VERSION ""

NS_ :

BS_:

BU_: BMS Third_Party_Device

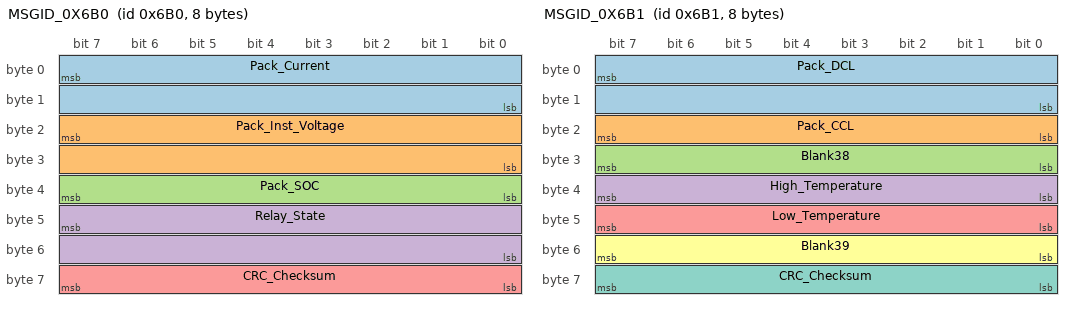
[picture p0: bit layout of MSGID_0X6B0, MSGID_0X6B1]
BO_ 1712 MSGID_0X6B0: 8 BMS
 SG_ Pack_Current : 7|16@0+ (0.1,0) [0|0] "Amps"  Third_Party_Device
 SG_ Pack_Inst_Voltage : 23|16@0+ (0.1,0) [0|0] "Volts"  Third_Party_Device
 SG_ Pack_SOC : 39|8@0+ (0.5,0) [0|0] "Percent"  Third_Party_Device
 SG_ Relay_State : 47|16@0+ (1.0,0) [0|0] ""  Third_Party_Device
 SG_ CRC_Checksum : 63|8@0+ (1.0,1720) [0|0] ""  Third_Party_Device

BO_ 1713 MSGID_0X6B1: 8 BMS
 SG_ Pack_DCL : 7|16@0+ (1.0,0) [0|0] "Amps"  Third_Party_Device
 SG_ Pack_CCL : 23|8@0+ (1.0,0) [0|0] "Amps"  Third_Party_Device
 SG_ Blank38 : 31|8@0+ (1.0,0) [0|0] ""  Third_Party_Device
 SG_ High_Temperature : 39|8@0+ (1.0,0) [0|0] "Celsius"  Third_Party_Device
 SG_ Low_Temperature : 47|8@0+ (1.0,0) [0|0] "Celsius"  Third_Party_Device
 SG_ Blank39 : 55|8@0+ (1.0,0) [0|0] ""  Third_Party_Device
 SG_ CRC_Checksum : 63|8@0+ (1.0,1721) [0|0] ""  Third_Party_Device

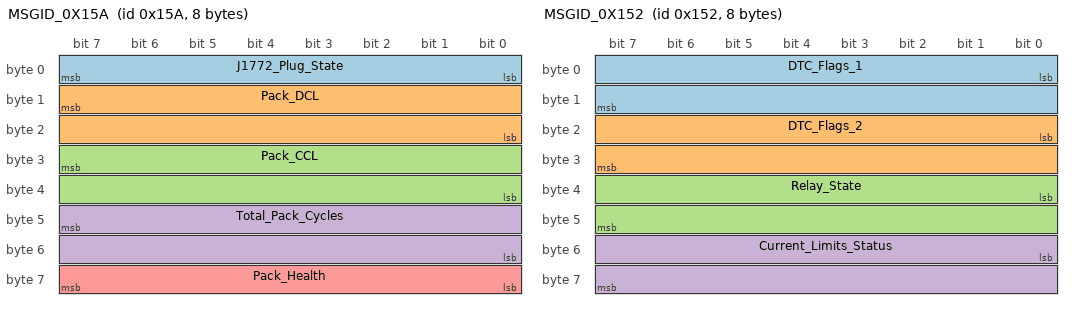
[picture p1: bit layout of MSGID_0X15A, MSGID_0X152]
BO_ 346 MSGID_0X15A: 8 BMS
 SG_ J1772_Plug_State : 7|8@0+ (1.0,0) [0|0] ""  Third_Party_Device
 SG_ Pack_DCL : 15|16@0+ (1.0,0) [0|0] "Amps"  Third_Party_Device
 SG_ Pack_CCL : 31|16@0+ (1.0,0) [0|0] "Amps"  Third_Party_Device
 SG_ Total_Pack_Cycles : 47|16@0+ (1.0,0) [0|0] "Num"  Third_Party_Device
 SG_ Pack_Health : 63|8@0+ (1.0,0) [0|0] "Percent"  Third_Party_Device

BO_ 338 MSGID_0X152: 8 BMS
 SG_ DTC_Flags_1 : 0|16@1+ (1.0,0) [0|0] ""  Third_Party_Device
 SG_ DTC_Flags_2 : 16|16@1+ (1.0,0) [0|0] ""  Third_Party_Device
 SG_ Relay_State : 32|16@1+ (1.0,0) [0|0] ""  Third_Party_Device
 SG_ Current_Limits_Status : 48|16@1+ (1.0,0) [0|0] ""  Third_Party_Device

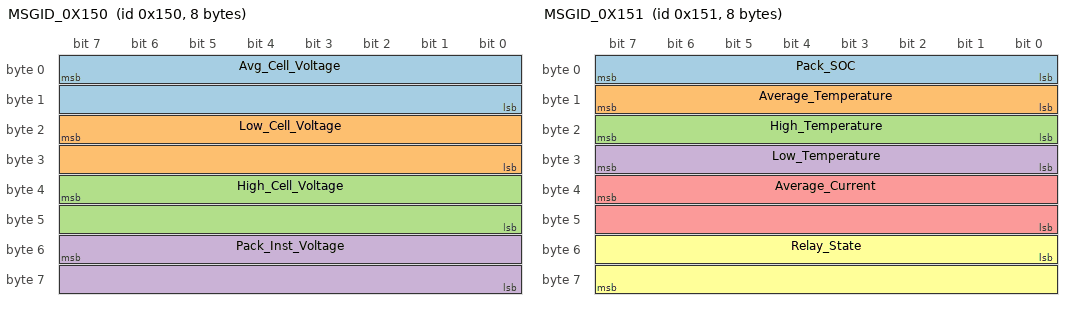
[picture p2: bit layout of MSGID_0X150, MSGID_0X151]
BO_ 336 MSGID_0X150: 8 BMS
 SG_ Avg_Cell_Voltage : 7|16@0+ (1.0E-4,0) [0|0] "Volts"  Third_Party_Device
 SG_ Low_Cell_Voltage : 23|16@0+ (1.0E-4,0) [0|0] "Volts"  Third_Party_Device
 SG_ High_Cell_Voltage : 39|16@0+ (1.0E-4,0) [0|0] "Volts"  Third_Party_Device
 SG_ Pack_Inst_Voltage : 55|16@0+ (0.1,0) [0|0] "Volts"  Third_Party_Device

BO_ 337 MSGID_0X151: 8 BMS
 SG_ Pack_SOC : 7|8@0+ (0.5,0) [0|0] "Percent"  Third_Party_Device
 SG_ Average_Temperature : 15|8@0+ (1.0,0) [0|0] "Celsius"  Third_Party_Device
 SG_ High_Temperature : 23|8@0+ (1.0,0) [0|0] "Celsius"  Third_Party_Device
 SG_ Low_Temperature : 31|8@0+ (1.0,0) [0|0] "Celsius"  Third_Party_Device
 SG_ Average_Current : 39|16@0+ (0.1,0) [0|0] "Amps"  Third_Party_Device
 SG_ Relay_State : 48|16@1+ (1.0,0) [0|0] ""  Third_Party_Device

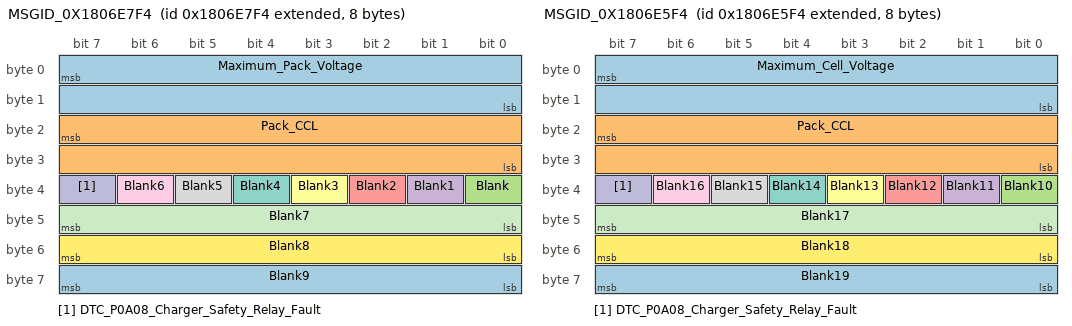
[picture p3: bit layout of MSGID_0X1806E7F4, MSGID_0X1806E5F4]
BO_ 2550589428 MSGID_0X1806E7F4: 8 BMS
 SG_ Maximum_Pack_Voltage : 7|16@0+ (0.1,0) [0|0] "Volts"  Third_Party_Device
 SG_ Pack_CCL : 23|16@0+ (0.1,0) [0|0] "Amps"  Third_Party_Device
 SG_ Blank : 32|1@1+ (1.0,0) [0|1] ""  Third_Party_Device
 SG_ Blank1 : 33|1@1+ (1.0,0) [0|1] ""  Third_Party_Device
 SG_ Blank2 : 34|1@1+ (1.0,0) [0|1] ""  Third_Party_Device
 SG_ Blank3 : 35|1@1+ (1.0,0) [0|1] ""  Third_Party_Device
 SG_ Blank4 : 36|1@1+ (1.0,0) [0|1] ""  Third_Party_Device
 SG_ Blank5 : 37|1@1+ (1.0,0) [0|1] ""  Third_Party_Device
 SG_ Blank6 : 38|1@1+ (1.0,0) [0|1] ""  Third_Party_Device
 SG_ DTC_P0A08_Charger_Safety_Relay_Fault : 39|1@1+ (1.0,0) [0|1] ""  Third_Party_Device
 SG_ Blank7 : 47|8@0+ (0.1,0) [0|0] ""  Third_Party_Device
 SG_ Blank8 : 55|8@0+ (1.0,0) [0|0] ""  Third_Party_Device
 SG_ Blank9 : 63|8@0+ (1.0,0) [0|0] ""  Third_Party_Device

BO_ 2550588916 MSGID_0X1806E5F4: 8 BMS
 SG_ Maximum_Cell_Voltage : 7|16@0+ (0.002777777777777778,0) [0|0] "Volts"  Third_Party_Device
 SG_ Pack_CCL : 23|16@0+ (0.1,0) [0|0] "Amps"  Third_Party_Device
 SG_ Blank10 : 32|1@1+ (1.0,0) [0|1] ""  Third_Party_Device
 SG_ Blank11 : 33|1@1+ (1.0,0) [0|1] ""  Third_Party_Device
 SG_ Blank12 : 34|1@1+ (1.0,0) [0|1] ""  Third_Party_Device
 SG_ Blank13 : 35|1@1+ (1.0,0) [0|1] ""  Third_Party_Device
 SG_ Blank14 : 36|1@1+ (1.0,0) [0|1] ""  Third_Party_Device
 SG_ Blank15 : 37|1@1+ (1.0,0) [0|1] ""  Third_Party_Device
 SG_ Blank16 : 38|1@1+ (1.0,0) [0|1] ""  Third_Party_Device
 SG_ DTC_P0A08_Charger_Safety_Relay_Fault : 39|1@1+ (1.0,0) [0|1] ""  Third_Party_Device
 SG_ Blank17 : 47|8@0+ (0.1,0) [0| 0] ""  Third_Party_Device
 SG_ Blank18 : 55|8@0+ (1.0,0) [0|0] ""  Third_Party_Device
 SG_ Blank19 : 63|8@0+ (1.0,0) [0|0] ""  Third_Party_Device

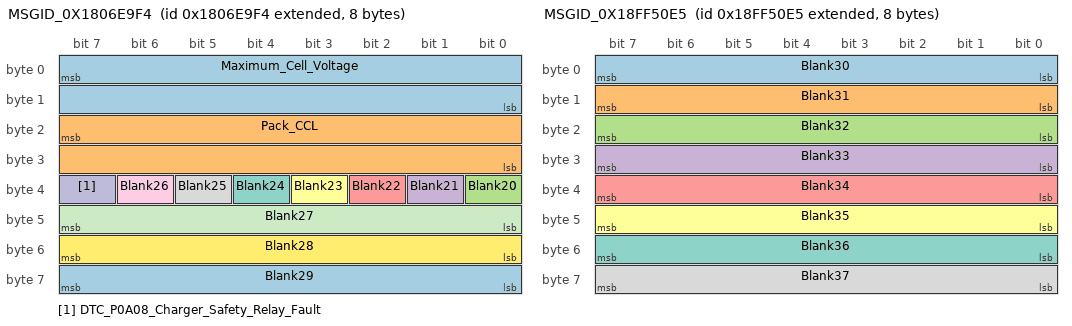
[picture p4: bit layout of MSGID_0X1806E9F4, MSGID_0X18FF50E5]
BO_ 2550589940 MSGID_0X1806E9F4: 8 BMS
 SG_ Maximum_Cell_Voltage : 7|16@0+ (0.002777777777777778,0) [0|0] "Volts"  Third_Party_Device
 SG_ Pack_CCL : 23|16@0+ (0.1,0) [0|0] "Amps"  Third_Party_Device
 SG_ Blank20 : 32|1@1+ (1.0,0) [0|1] ""  Third_Party_Device
 SG_ Blank21 : 33|1@1+ (1.0,0) [0|1] ""  Third_Party_Device
 SG_ Blank22 : 34|1@1+ (1.0,0) [0|1] ""  Third_Party_Device
 SG_ Blank23 : 35|1@1+ (1.0,0) [0|1] ""  Third_Party_Device
 SG_ Blank24 : 36|1@1+ (1.0,0) [0|1] ""  Third_Party_Device
 SG_ Blank25 : 37|1@1+ (1.0,0) [0|1] ""  Third_Party_Device
 SG_ Blank26 : 38|1@1+ (1.0,0) [0|1] ""  Third_Party_Device
 SG_ DTC_P0A08_Charger_Safety_Relay_Fault : 39|1@1+ (1.0,0) [0|1] ""  Third_Party_Device
 SG_ Blank27 : 47|8@0+ (1.0,0) [0|0] ""  Third_Party_Device
 SG_ Blank28 : 55|8@0+ (1.0,0) [0|0] ""  Third_Party_Device
 SG_ Blank29 : 63|8@0+ (1.0,0) [0|0] ""  Third_Party_Device

BO_ 2566869221 MSGID_0X18FF50E5: 8 Third_Party_Device
 SG_ Blank30 : 7|8@0+ (1.0,0) [0|0] ""  BMS
 SG_ Blank31 : 15|8@0+ (1.0,0) [0|0] ""  BMS
 SG_ Blank32 : 23|8@0+ (1.0,0) [0|0] ""  BMS
 SG_ Blank33 : 31|8@0+ (1.0,0) [0|0] ""  BMS
 SG_ Blank34 : 39|8@0+ (1.0,0) [0|0] ""  BMS
 SG_ Blank35 : 47|8@0+ (1.0,0) [0|0] ""  BMS
 SG_ Blank36 : 55|8@0+ (1.0,0) [0|0] ""  BMS
 SG_ Blank37 : 63|8@0+ (1.0,0) [0|0] ""  BMS

CM_ BO_ 1712 "This ID Transmits at 8 ms.";
CM_ BO_ 1713 "This ID Transmits at 104 ms.";
CM_ BO_ 346 "This ID Transmits at 80 ms.";
CM_ BO_ 338 "This ID Transmits at 120 ms.";
CM_ BO_ 336 "This ID Transmits at 80 ms.";
CM_ BO_ 337 "This ID Transmits at 112 ms.";
CM_ BO_ 2550589428 "This ID Transmits at 808 ms.";
CM_ BO_ 2550588916 "This ID Transmits at 808 ms.";
CM_ BO_ 2550589940 "This ID Transmits at 808 ms.";
